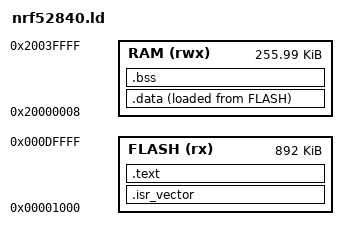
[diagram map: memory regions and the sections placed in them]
MEMORY
{
  FLASH (rx) : ORIGIN = 0x00001000, LENGTH = 0xDF000
  RAM (rwx)  : ORIGIN = 0x20000008, LENGTH = 0x3FFF8
}

SECTIONS
{
  .isr_vector :
  {
    KEEP(*(.isr_vector))
  } > FLASH

  .text :
  {
    *(.text*)
    *(.rodata*)
  } > FLASH

  _sidata = LOADADDR(.data);

  .data :
  {
    _sdata = .;
    *(.data*)
    _edata = .;
  } > RAM AT > FLASH

  .bss :
  {
    _sbss = .;
    *(.bss*)
    *(COMMON)
    _ebss = .;
  } > RAM

  . = ALIGN(8);
  _estack = ORIGIN(RAM) + LENGTH(RAM);
}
